# MM32G0001 register map
File version: 0.9.0
CPU: CM0 r0p0, little endian, no MPU, no FPU, 2 interrupt priority bits
Registers are 32-bit, read-write, reset 0x0 unless marked. A register's access mark holds for its fields unless they carry their own. Offsets are from the block's base; [hi:lo] are bit positions; {n}, {i} and the like mark numbered series.

## DBG — Debug support
Base 0x40013400
0x00 IDCODE ro
  [31:0] DEV_ID — Device identifier
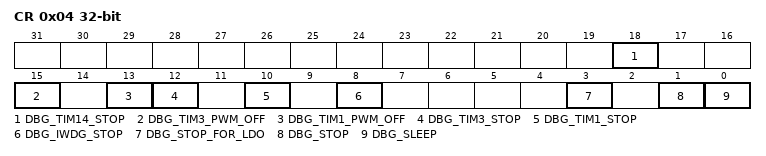
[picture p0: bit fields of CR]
0x04 CR — Control Register
  [18] DBG_TIM14_STOP — TIM14 counter stopped when core is halted
  [15] DBG_TIM3_PWM_OFF — TIM3 PWM ouput 0 when core is halted
  [13] DBG_TIM1_PWM_OFF — TIM1 PWM ouput 0 when core is halted
  [12] DBG_TIM3_STOP — TIM3 counter stopped when core is halted
  [10] DBG_TIM1_STOP — TIM1 counter stopped when core is halted
  [8] DBG_IWDG_STOP — Debug independent watchdog stopped when core is stopped
  [3] DBG_STOP_FOR_LDO — Debug Stop Ldo
  [1] DBG_STOP — Debug Stop mode
  [0] DBG_SLEEP — Can be configured as any channel from ch0 to 9, 14 to 15.

## DEVICE
Base 0x1FFFF7E8
0x00 UID1 ro — Configuration register
  [31:0] U_ID — 31:0 unique ID bits
0x04 UID2 ro — Configuration register
  [31:0] U_ID — 63:32 unique ID bits
0x08 UID3 ro — Configuration register
  [31:0] U_ID — 95:64 unique ID bits

## SYSCFG — System Configurationcontroller
Base 0x40010000
0x00 CFGR — Configuration register
  [1:0] MEM_MODE — *D0
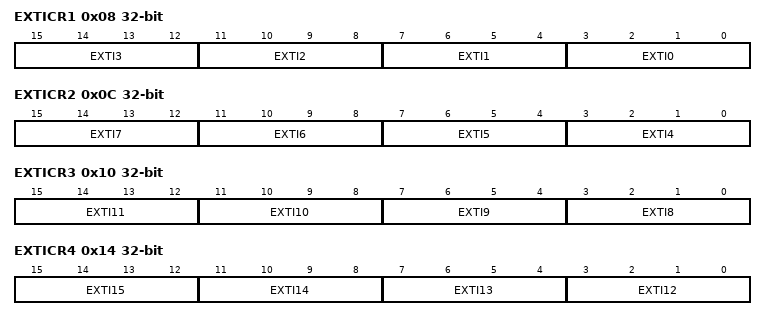
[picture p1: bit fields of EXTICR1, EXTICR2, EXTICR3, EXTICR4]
0x08 EXTICR1 — External interrupt configuration register 1
  [15:12] EXTI3 — EXTI 3 configuration
  [11:8] EXTI2 — EXTI 2 configuration
  [7:4] EXTI1 — EXTI 1 configuration
  [3:0] EXTI0 — EXTI_Memory Remap Config
0x0C EXTICR2 — External interrupt configuration register 2
  [4n-13:4n-16] EXTI{n} (n=4..7) — EXTI {n} configuration
0x10 EXTICR3 — External interrupt configuration register 3
  [4n-29:4n-32] EXTI{n} (n=8..11) — EXTI {n} configuration
0x14 EXTICR4 — External interrupt configuration register 4
  [4n-45:4n-48] EXTI{n} (n=12..15) — EXTI {n} configuration
0x18 PADHYS — PAD configuration register
  [16] I2C1_mode_sel — I2C1 mode selection

## EXTI — External interrupt/event controller
Base 0x40010400
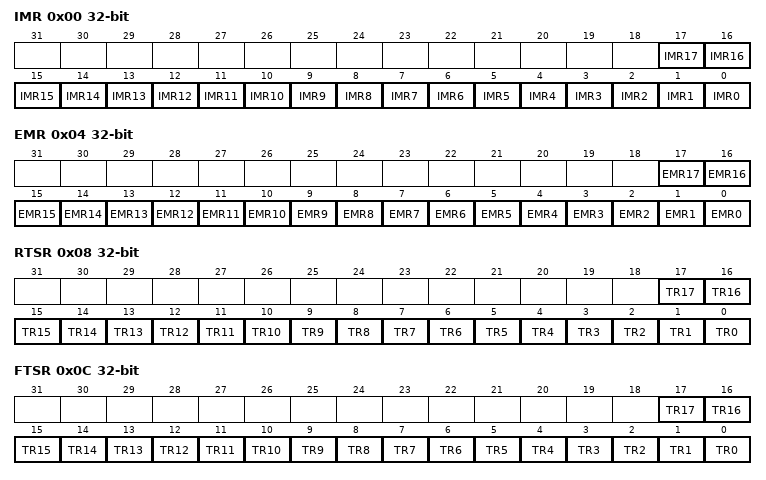
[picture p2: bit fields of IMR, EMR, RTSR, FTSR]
0x00 IMR — Interrupt mask register
  [n] IMR{n} (n=0..17) — Interrupt Mask on line {n}
0x04 EMR — Event mask register
  [n] EMR{n} (n=0..17) — Event Mask on line {n}
0x08 RTSR — Rising trigger selection register
  [n] TR{n} (n=0..17) — Rising trigger event configuration bit of line {n}
0x0C FTSR — Falling trigger selection register
  [n] TR{n} (n=0..17) — Falling trigger event configuration bit of line {n}
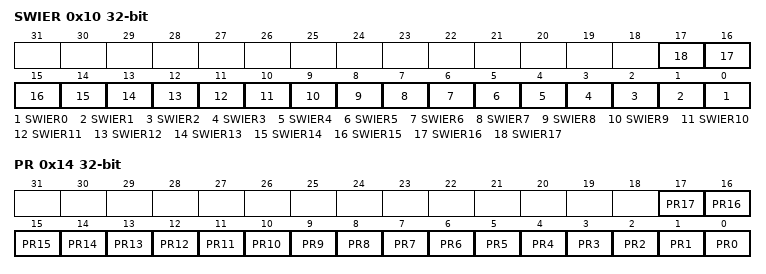
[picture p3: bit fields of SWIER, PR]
0x10 SWIER — Software interrupt event register
  [n] SWIER{n} (n=0..17) — Software interrupt on line {n}
0x14 PR — Pending register
  [n] PR{n} (n=0..17) — Pending bit

## FLASH
Base 0x40022000
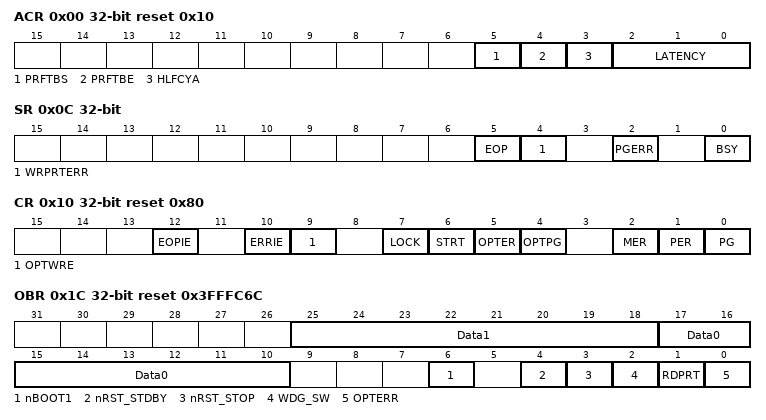
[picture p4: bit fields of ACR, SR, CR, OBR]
0x00 ACR reset 0x10 — Flash access control register
  [5] PRFTBS — Prefetch buffer status
  [4] PRFTBE — Prefetch buffer enable
  [3] HLFCYA — Flash half cycle access enable
  [2:0] LATENCY
0x04 KEYR wo — Flash key
  [31:0] FKEYR
0x08 OPTKEYR wo — Option byte key
0x0C SR — Flash status register
  [5] EOP — End of operation
  [4] WRPRTERR — Write protection error
  [2] PGERR — Programming error
  [0] BSY — Busy
0x10 CR reset 0x80 — Flash control register
  [12] EOPIE — End of operation interrupt enable
  [10] ERRIE — Error interrupt enable
  [9] OPTWRE — Option byte write enable
  [7] LOCK
  [6] STRT — Start
  [5] OPTER — Option byte erase
  [4] OPTPG — Option byte programming
  [2] MER — Mass erase
  [1] PER — Page erase
  [0] PG — Programming
0x14 AR wo — Flash address register
  [31:0] FAR — Flash Address
0x1C OBR ro reset 0x3FFFC6C — Option byte register
  [25:18] Data1
  [17:10] Data0
  [6] nBOOT1 — User option bytes
  [4] nRST_STDBY — User option bytes
  [3] nRST_STOP — User option bytes
  [2] WDG_SW — User option bytes
  [1] RDPRT — Read protection level status
  [0] OPTERR — Option byte error
0x20 WRPR ro reset 0xFFFFFFFF — Write protect register
  [3:0] WRP — Write protect

## GPIOA — General purpose I/O
Base 0x48000000
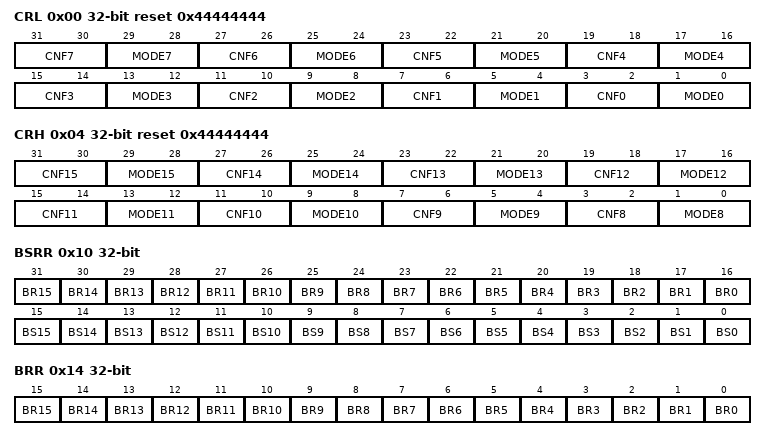
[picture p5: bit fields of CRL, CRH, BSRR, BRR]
0x00 CRL reset 0x44444444 — configuration low register
  [4n+3:4n+2] CNF{n} (n=0..7) — Port {n} configuration bits
  [4n+1:4n] MODE{n} (n=0..7) — Port {n} mode bits
0x04 CRH reset 0x44444444 — configuration high register
  [4n-29:4n-30] CNF{n} (n=8..15) — Port {n} configuration bits
  [4n-31:4n-32] MODE{n} (n=8..15) — Port {n} mode bits
0x08 IDR ro — input data register
  [15:0] IDR — Port input data
0x0C ODR — output data register
  [15:0] ODR — Port output data
0x10 BSRR wo — bit set/reset register
  [n+16] BR{n} (n=0..15) — Port x Reset bit {n}
  [n] BS{n} (n=0..15) — Port x Set bit {n}
0x14 BRR wo — bit reset register
  [n] BR{n} (n=0..15) — Port x Reset bit {n}
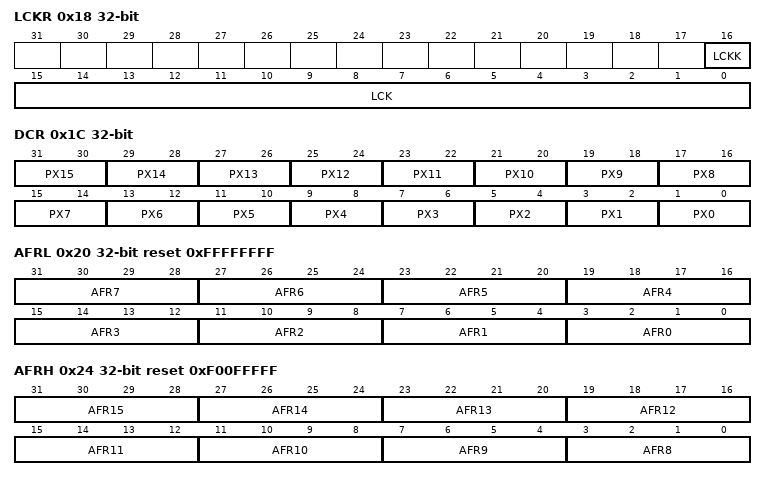
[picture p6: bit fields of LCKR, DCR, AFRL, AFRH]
0x18 LCKR — Port configuration lock register
  [16] LCKK — Lock key
  [15:0] LCK — Port x Lock bit y
0x1C DCR — Port output open drain control register
  [2n+1:2n] PX{n} (n=0..15)
0x20 AFRL reset 0xFFFFFFFF — Port Multiplexing Function Low Register
  [4n+3:4n] AFR{n} (n=0..7) — Multiplexing function selection for bit {n} of portx
0x24 AFRH reset 0xF00FFFFF — Port Multiplexing Function High Register
  [4n-29:4n-32] AFR{n} (n=8..15) — Multiplexing function selection for bit {n} of portx

## GPIOB — General purpose I/O
Base 0x48000400
Registers as GPIOA, without CRH; these are added or differ:
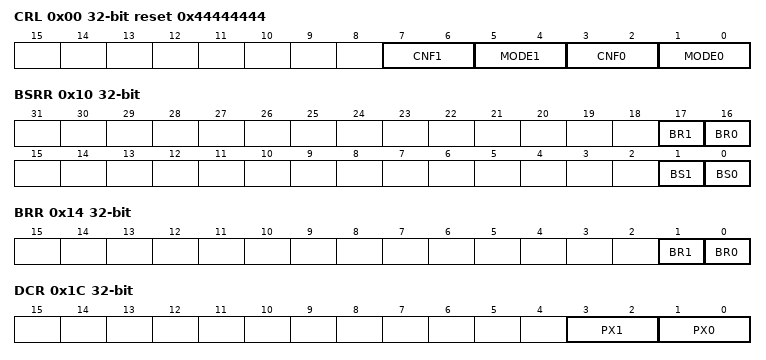
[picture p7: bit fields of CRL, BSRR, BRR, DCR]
0x00 CRL reset 0x44444444 — configuration low register
  [7:6] CNF1 — Port 1 configuration bits
  [5:4] MODE1 — Port 1 mode bits
  [3:2] CNF0 — Port 0 configuration bits
  [1:0] MODE0 — Port 0 mode bits
0x10 BSRR wo — bit set/reset register
  [17] BR1 — Port x Reset bit 1
  [16] BR0 — Port x Reset bit 0
  [1] BS1 — Port x Set bit 1
  [0] BS0 — Port x Set bit 0
0x14 BRR wo — bit reset register
  [1] BR1 — Port x Reset bit 1
  [0] BR0 — Port x Reset bit 0
0x1C DCR — Port output open drain control register
  [3:2] PX1, [1:0] PX0
